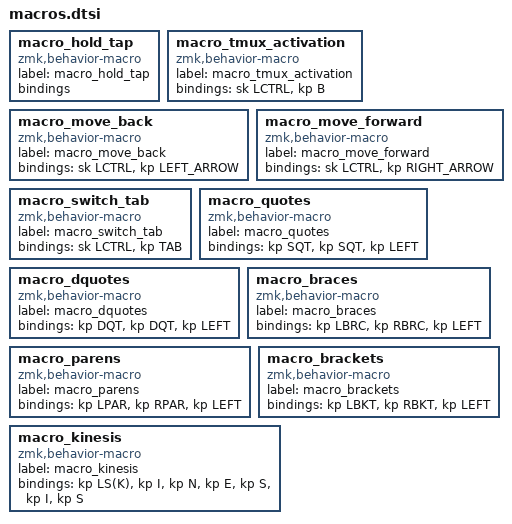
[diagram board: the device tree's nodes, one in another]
macro_hold_tap: macro_hold_tap{
compatible = "zmk,behavior-macro";
label = "macro_hold_tap";
#binding-cells = <0>;
bindings = ;
};
macro_tmux_activation: macro_tmux_activation{
compatible = "zmk,behavior-macro";
label = "macro_tmux_activation";
#binding-cells = <0>;
bindings = <&sk LCTRL>, <&kp B>;
};
macro_move_back: macro_move_back{
compatible = "zmk,behavior-macro";
label = "macro_move_back";
#binding-cells = <0>;
bindings = <&sk LCTRL>, <&kp LEFT_ARROW>;
};
macro_move_forward: macro_move_forward{
compatible = "zmk,behavior-macro";
label = "macro_move_forward";
#binding-cells = <0>;
bindings = <&sk LCTRL>, <&kp RIGHT_ARROW>;
};
macro_switch_tab: macro_switch_tab{
compatible = "zmk,behavior-macro";
label = "macro_switch_tab";
#binding-cells = <0>;
bindings = <&sk LCTRL>, <&kp TAB>;
};
macro_quotes: macro_quotes{
compatible = "zmk,behavior-macro";
label = "macro_quotes";
#binding-cells = <0>;
bindings = <&kp SQT>, <&kp SQT>, <&kp LEFT>;
};
macro_dquotes: macro_dquotes{
compatible = "zmk,behavior-macro";
label = "macro_dquotes";
#binding-cells = <0>;
bindings = <&kp DQT>, <&kp DQT>, <&kp LEFT>;
};
macro_braces: macro_braces{
compatible = "zmk,behavior-macro";
label = "macro_braces";
#binding-cells = <0>;
bindings = <&kp LBRC>, <&kp RBRC>, <&kp LEFT>;
};
macro_parens: macro_parens{
compatible = "zmk,behavior-macro";
label = "macro_parens";
#binding-cells = <0>;
bindings = <&kp LPAR>, <&kp RPAR>, <&kp LEFT>;
};
macro_brackets: macro_brackets{
compatible = "zmk,behavior-macro";
label = "macro_brackets";
#binding-cells = <0>;
bindings = <&kp LBKT>, <&kp RBKT>, <&kp LEFT>;
};
macro_kinesis: macro_kinesis{
compatible = "zmk,behavior-macro";
label = "macro_kinesis";
#binding-cells = <0>;
bindings = <&kp LS(K)>, <&kp I>, <&kp N>, <&kp E>, <&kp S>, <&kp I>, <&kp S>;
};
